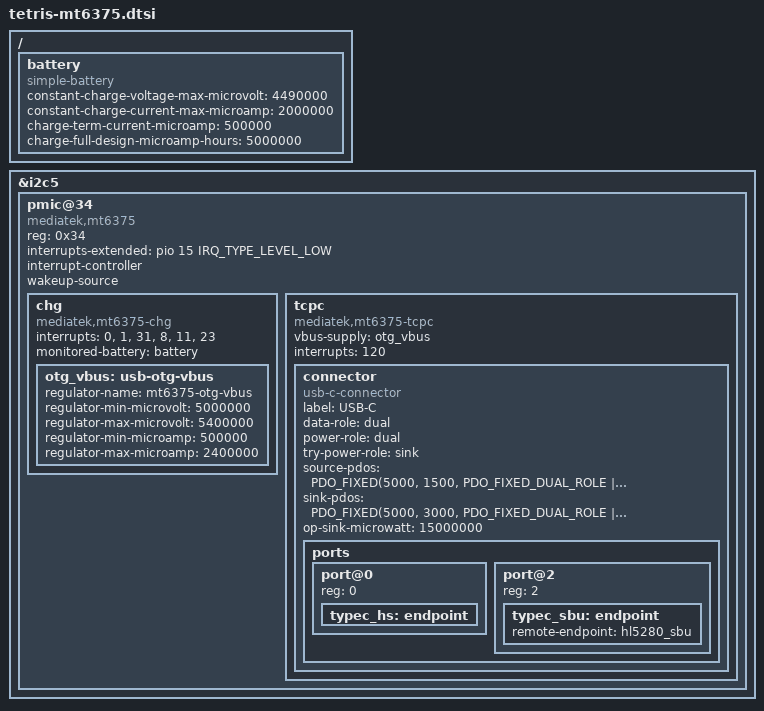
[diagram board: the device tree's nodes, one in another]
// SPDX-License-Identifier: GPL-2.0-only
/*
 * CMF Phone 1 (Tetris): MT6375 SubPMIC on I2C5, for the mainline-style drivers in
 * mainline/drivers/mfd/mt6375.c (core) and mainline/drivers/usb/typec/tcpm/tcpci_mt6375.c
 * (Type-C port controller on the TCPCI core).
 *
 * The vendor tree uses the same compatibles; its TCPC node carries the vendor PD stack's
 * properties (tcpc,*, wd,* water detection, pd-data), which mainline describes with a
 * usb-c-connector instead. Interrupt numbers are the vendor's (dt-bindings/mfd/mt6375.h):
 * 120 pd_evt. The core's own interrupt is EINT 15, level low.
 *
 * PD: sink 5 V only for now; higher voltages need the charge pump (SC8541) and the fast
 * charging logic of the vendor framework. VBUS as source (OTG) is the charger's boost.
 *
 * Charger (mainline/drivers/power/supply/mt6375-charger.c): the charge limits come from
 * the battery node, the values the vendor tree sets (CV 4.49 V, 2 A, end of charge at
 * 500 mA); the vendor tree also sets MIVR 4.4 V, 14.5 V VBUS OVP, a 10 h timer and IR
 * compensation 32 mV / 16.7 mOhm, which the driver programs itself. The OTG boost keeps
 * the voltage the bootloader left (5.4 V on this phone) unless constrained here.
 */
#include <dt-bindings/interrupt-controller/irq.h>
#include <dt-bindings/usb/pd.h>

/ {
	battery: battery {
		compatible = "simple-battery";
		constant-charge-voltage-max-microvolt = <4490000>;
		constant-charge-current-max-microamp = <2000000>;
		charge-term-current-microamp = <500000>;
		charge-full-design-microamp-hours = <5000000>;
	};
};

&i2c5 {
	pmic@34 {
		compatible = "mediatek,mt6375";
		reg = <0x34>;
		interrupts-extended = <&pio 15 IRQ_TYPE_LEVEL_LOW>;
		interrupt-controller;
		#interrupt-cells = <1>;
		wakeup-source;

		chg {
			compatible = "mediatek,mt6375-chg";
			interrupts = <0>, <1>, <31>, <8>, <11>, <23>;
			interrupt-names = "fl_pwr_rdy", "fl_detach", "fl_bc12_dn",
					  "fl_vbus_ov", "fl_chg_tout", "fl_wdt";
			monitored-battery = <&battery>;

			otg_vbus: usb-otg-vbus {
				regulator-name = "mt6375-otg-vbus";
				regulator-min-microvolt = <5000000>;
				regulator-max-microvolt = <5400000>;
				regulator-min-microamp = <500000>;
				regulator-max-microamp = <2400000>;
			};
		};

		tcpc {
			compatible = "mediatek,mt6375-tcpc";
			vbus-supply = <&otg_vbus>;
			interrupts = <120>;
			interrupt-names = "pd_evt";

			connector {
				compatible = "usb-c-connector";
				label = "USB-C";
				data-role = "dual";
				power-role = "dual";
				try-power-role = "sink";
				source-pdos = <PDO_FIXED(5000, 1500, PDO_FIXED_DUAL_ROLE | PDO_FIXED_DATA_SWAP |
								 PDO_FIXED_USB_COMM)>;
				sink-pdos = <PDO_FIXED(5000, 3000, PDO_FIXED_DUAL_ROLE | PDO_FIXED_DATA_SWAP |
							       PDO_FIXED_USB_COMM)>;
				op-sink-microwatt = <15000000>;

				ports {
					#address-cells = <1>;
					#size-cells = <0>;

					port@0 {
						reg = <0>;
						typec_hs: endpoint {
							/* remote-endpoint = <&usb_hs_role_switch>; (mtu3, no mainline node yet) */
						};
					};

					port@2 {
						reg = <2>;
						typec_sbu: endpoint {
							remote-endpoint = <&hl5280_sbu>;
						};
					};
				};
			};
		};
	};
};
